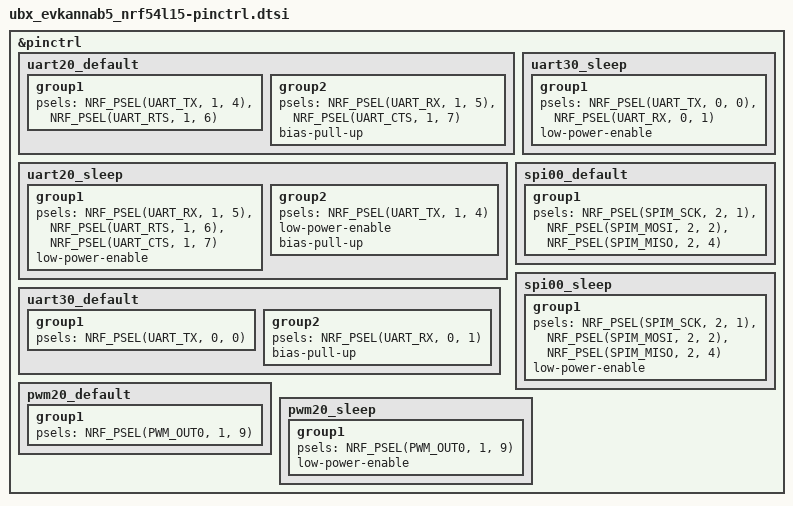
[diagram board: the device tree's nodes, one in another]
/*
 * Copyright (c) 2026 u-blox AG
 * SPDX-License-Identifier: Apache-2.0
 */

&pinctrl {
	/omit-if-no-ref/ uart20_default: uart20_default {
		group1 {
			psels = <NRF_PSEL(UART_TX, 1, 4)>,
				<NRF_PSEL(UART_RTS, 1, 6)>;
		};

		group2 {
			psels = <NRF_PSEL(UART_RX, 1, 5)>,
				<NRF_PSEL(UART_CTS, 1, 7)>;
			bias-pull-up;
		};
	};

	/omit-if-no-ref/ uart20_sleep: uart20_sleep {
		group1 {
			psels = <NRF_PSEL(UART_RX, 1, 5)>,
				<NRF_PSEL(UART_RTS, 1, 6)>,
				<NRF_PSEL(UART_CTS, 1, 7)>;
			low-power-enable;
		};

		group2 {
			psels = <NRF_PSEL(UART_TX, 1, 4)>;
			low-power-enable;
			bias-pull-up;
		};
	};

	/* UART0 is only wired to TxD/RxD on the pin header, no flow control */
	/omit-if-no-ref/ uart30_default: uart30_default {
		group1 {
			psels = <NRF_PSEL(UART_TX, 0, 0)>;
		};

		group2 {
			psels = <NRF_PSEL(UART_RX, 0, 1)>;
			bias-pull-up;
		};
	};

	/omit-if-no-ref/ uart30_sleep: uart30_sleep {
		group1 {
			psels = <NRF_PSEL(UART_TX, 0, 0)>,
				<NRF_PSEL(UART_RX, 0, 1)>;
			low-power-enable;
		};
	};

	/omit-if-no-ref/ spi00_default: spi00_default {
		group1 {
			psels = <NRF_PSEL(SPIM_SCK, 2, 1)>,
				<NRF_PSEL(SPIM_MOSI, 2, 2)>,
				<NRF_PSEL(SPIM_MISO, 2, 4)>;
		};
	};

	/omit-if-no-ref/ spi00_sleep: spi00_sleep {
		group1 {
			psels = <NRF_PSEL(SPIM_SCK, 2, 1)>,
				<NRF_PSEL(SPIM_MOSI, 2, 2)>,
				<NRF_PSEL(SPIM_MISO, 2, 4)>;
			low-power-enable;
		};
	};

	/* Shares pin with the RGB LED blue channel (P1.09) */
	/omit-if-no-ref/ pwm20_default: pwm20_default {
		group1 {
			psels = <NRF_PSEL(PWM_OUT0, 1, 9)>;
		};
	};

	/omit-if-no-ref/ pwm20_sleep: pwm20_sleep {
		group1 {
			psels = <NRF_PSEL(PWM_OUT0, 1, 9)>;
			low-power-enable;
		};
	};
};
